# GD32E53x register map
File version: 1.0
CPU: CM33 r0p4, little endian, MPU, FPU, 4 interrupt priority bits
Registers are 32-bit, read-write, reset 0x0 unless marked. A register's access mark holds for its fields unless they carry their own. Offsets are from the block's base; [hi:lo] are bit positions; {n}, {i} and the like mark numbered series; 'fields as' and 'values as' point back to an identical list.

## RTC — Real time clock
Base 0x40002800
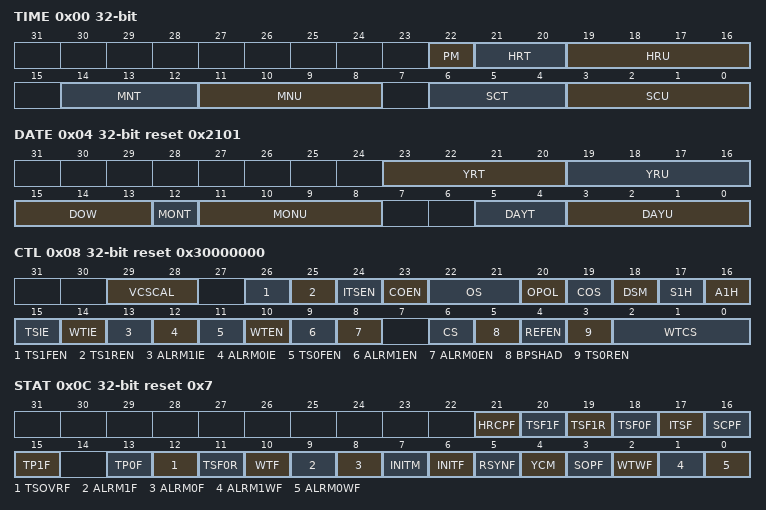
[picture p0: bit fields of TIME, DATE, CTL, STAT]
0x00 TIME
  [22] PM — AM/PM mark
  [21:20] HRT — Hour tens in BCD code
  [19:16] HRU — Hour units in BCD code
  [14:12] MNT — Minute tens in BCD code
  [11:8] MNU — Minute units in BCD code
  [6:4] SCT — Second tens in BCD code
  [3:0] SCU — Second units in BCD code
0x04 DATE reset 0x2101
  [23:20] YRT — Year tens in BCD code
  [19:16] YRU — Year units in BCD code
  [15:13] DOW — Days of the week
  [12] MONT — Month tens in BCD code
  [11:8] MONU — Month units in BCD code
  [5:4] DAYT — Day tens in BCD code
  [3:0] DAYU — Day units in BCD code
0x08 CTL access per field reset 0x30000000 — Control register
  [29:28] VCSCAL rw — BLDO voltage level selection
  [26] TS1FEN rw — RTC_TS1 time-stamp event falling edge enable
  [25] TS1REN rw — RTC_TS1 time-stamp event rising edge enable
  [24] ITSEN rw — Internal time-stamp event enable
  [23] COEN rw — Calibration output enable
  [22:21] OS rw — Output selection
  [20] OPOL rw — Output polarity
  [19] COS rw — Calibration output selection
  [18] DSM rw — Daylight saving mark
  [17] S1H wo — Subtract 1 hour(winter time change)
  [16] A1H wo — Add 1 hour(summer time change)
  [15] TSIE rw — Time-stamp interrupt enable
  [14] WTIE rw — Auto-wakeup timer interrupt enable
  [13] ALRM1IE rw — RTC alarm 1 interrupt enable
  [12] ALRM0IE rw — RTC alarm 0 interrupt enable
  [11] TS0FEN rw — RTC_TS0 time-stamp event falling edge enable
  [10] WTEN rw — Auto-wakeup timer function enable
  [9] ALRM1EN rw — Alarm 1 function enable
  [8] ALRM0EN rw — Alarm 0 function enable
  [6] CS rw — Clock System
  [5] BPSHAD rw — Shadow registers bypass control
  [4] REFEN rw — Reference clock detection function enable
  [3] TS0REN rw — RTC_TS0 time-stamp event rising edge enable
  [2:0] WTCS rw — Auto-wakeup timer clock selection
0x0C STAT access per field reset 0x7 — Status register
  [21] HRCPF ro — High-resolution calibration pending flag
  [20] TSF1F rw — Time-stamp1 falling edge event flag
  [19] TSF1R rw — Time-stamp1 rising edge event flag
  [18] TSF0F rw — Time-stamp 0 falling edge event flag
  [17] ITSF rw — Internal timestamp flag
  [16] SCPF ro — Smooth calibration pending flag
  [15] TP1F rw — RTC_TAMP1 detected flag
  [13] TP0F rw — RTC_TAMP0 detected flag
  [12] TSOVRF rw — Time-stamp overflow flag
  [11] TSF0R rw — Time-stamp 0 event rising edge flag
  [10] WTF rw — Wakeup timer flag
  [9] ALRM1F rw — Alarm 1 occurs flag
  [8] ALRM0F rw — Alarm 0 occurs flag
  [7] INITM rw — Enter initialization mode
  [6] INITF ro — Initialization state flag
  [5] RSYNF rw — Register synchronization flag
  [4] YCM ro — Year configuration mark
  [3] SOPF ro — Shift function operation pending flag
  [2] WTWF ro — Wakeup timer write enable flag
  [1] ALRM1WF ro — Alarm 1 configuration can be write flag
  [0] ALRM0WF ro — Alarm 0 configuration can be write flag
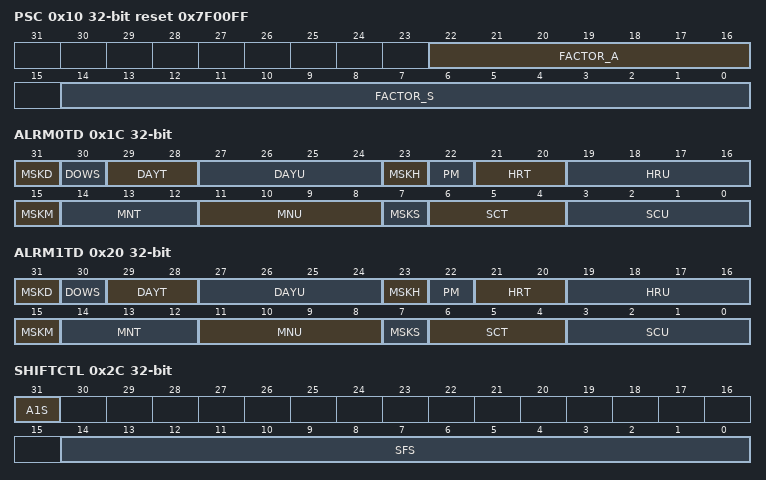
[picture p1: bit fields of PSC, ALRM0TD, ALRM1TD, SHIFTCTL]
0x10 PSC reset 0x7F00FF — Prescaler register
  [22:16] FACTOR_A — Asynchronous prescaler factor
  [14:0] FACTOR_S — Synchronous prescaler factor
0x14 WUT reset 0xFFFF — Wakeup timer register
  [15:0] WTRV — Auto-wakeup timer reloads value.
0x1C ALRM0TD — Alarm 0 time and date register
  [31] MSKD — Alarm date mask bit
  [30] DOWS — Day of the week selected
  [29:28] DAYT — Date tens in BCD code
  [27:24] DAYU — Date units or week day in BCD code
  [23] MSKH — Alarm hour mask bit
  [22] PM — AM/PM flag
  [21:20] HRT — Hour tens in BCD code
  [19:16] HRU — Hour units in BCD code
  [15] MSKM — Alarm minutes mask bit
  [14:12] MNT — Minutes tens in BCD code
  [11:8] MNU — Minutes units in BCD code
  [7] MSKS — Alarm second mask bit
  [6:4] SCT — Second tens in BCD code
  [3:0] SCU — Second units in BCD code
0x20 ALRM1TD — Alarm 1 time and date register
  [31] MSKD — Alarm date mask bit
  [30] DOWS — Day of the week selected
  [29:28] DAYT — Day tens in BCD code
  [27:24] DAYU — Day units or week day in BCD code
  [23] MSKH — Alarm hour mask bit
  [22] PM — AM/PM flag
  [21:20] HRT — Hour tens in BCD code
  [19:16] HRU — Hour units in BCD code
  [15] MSKM — Alarm minutes mask bit
  [14:12] MNT — Minutes tens in BCD code
  [11:8] MNU — Minutes units in BCD code
  [7] MSKS — Alarm second mask bit
  [6:4] SCT — Second tens in BCD code
  [3:0] SCU — Second units in BCD code
0x24 WPK wo — Write protection key register
  [7:0] WPK — Key for write protection
0x28 SS ro — Sub second register
  [15:0] SSC — Sub second value
0x2C SHIFTCTL wo — Shift function control register
  [31] A1S — One second add
  [14:0] SFS — Subtract a fraction of a second
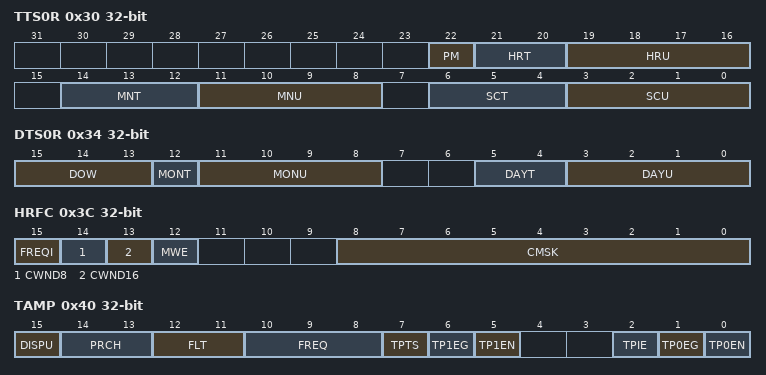
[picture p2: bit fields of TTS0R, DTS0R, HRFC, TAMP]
0x30 TTS0R ro — Time of time-stamp 0 rising register
  fields as TIME
0x34 DTS0R ro — Date of time-stamp 0 rising register
  [15:13] DOW — Days of the week
  [12] MONT — Month tens in BCD code
  [11:8] MONU — Month units in BCD code
  [5:4] DAYT — Day tens in BCD code
  [3:0] DAYU — Day units in BCD code
0x38 SSTS0R ro — Sub second of time-stamp 0 rising register
  [15:0] SSC — Sub second value
0x3C HRFC — High resolution frequency compensation register
  [15] FREQI — Increase RTC frequency by 488.5PPM
  [14] CWND8 — Frequency compensation window 8 second selected
  [13] CWND16 — Frequency compensation window 16 second selected
  [12] MWE — Multiple windows calibration enable.
  [8:0] CMSK — Calibration mask number
0x40 TAMP — Tamper register
  [15] DISPU — RTC_TAMPx pull up disable bit
  [14:13] PRCH — Pre-charge duration time of RTC_TAMPx
  [12:11] FLT — RTC_TAMPx filter count setting
  [10:8] FREQ — Sampling frequency of tamper event detection
  [7] TPTS — Make tamper function used for time-stamp 0 rising function
  [6] TP1EG — Tamper 1 event trigger edge
  [5] TP1EN — Tamper 1 detection enable
  [2] TPIE — Tamper detection interrupt enable
  [1] TP0EG — Tamper 0 event trigger edge
  [0] TP0EN — Tamper 0 detection enable
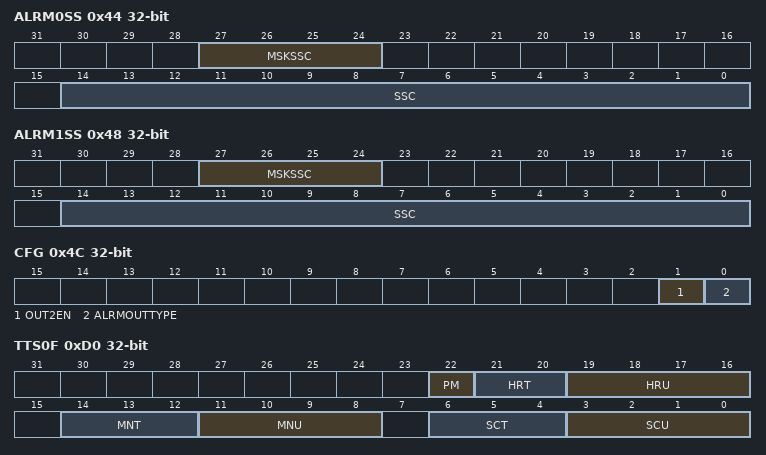
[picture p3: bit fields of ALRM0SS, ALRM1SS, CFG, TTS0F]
0x44 ALRM0SS — Alarm 0 sub second register
  [27:24] MSKSSC — Mask control bit of SSC
  [14:0] SSC — Alarm sub second value
0x48 ALRM1SS — Alarm 1 sub second register
  fields as ALRM0SS
0x4C CFG — Configuration register
  [1] OUT2EN — RTC_OUT pin select
  [0] ALRMOUTTYPE — RTC_ALARM Output Type
{0x50+4i} BKP{i} (i=0..3) — Backup registe {i}
  [31:0] DATA
0xD0 TTS0F ro — Time of time-stamp 0 falling register
  fields as TIME
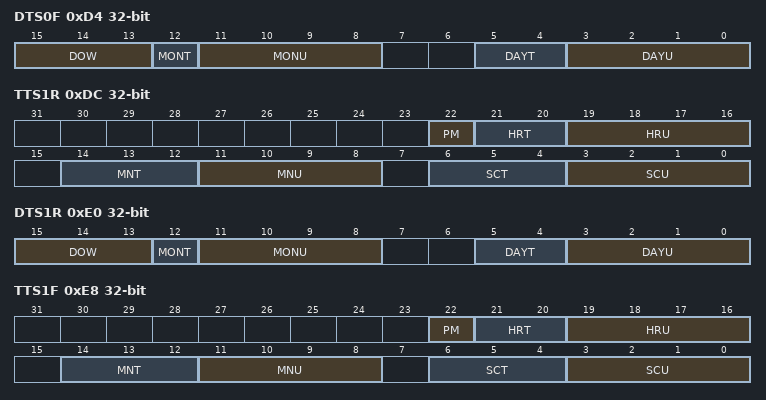
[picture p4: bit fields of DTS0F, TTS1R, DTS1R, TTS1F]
0xD4 DTS0F ro — Date of time-stamp 0 falling register
  fields as DTS0R
0xD8 SSTS0F ro — Sub second of time-stamp 0 falling register
  [15:0] SSC — Sub second value
0xDC TTS1R ro — Time of time-stamp 1 rising register
  fields as TIME
0xE0 DTS1R ro — Date of time-stamp 1 rising register
  fields as DTS0R
0xE4 SSTS1R ro — Sub second of time-stamp 1 rising register
  [15:0] SSC — Sub second value
0xE8 TTS1F ro — Time of time-stamp 1 falling register
  fields as TIME
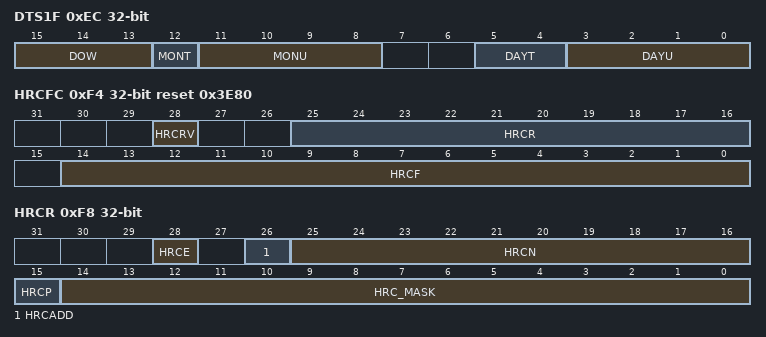
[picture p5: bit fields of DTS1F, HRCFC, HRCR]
0xEC DTS1F ro — Date of time-stamp 1 falling register
  fields as DTS0R
0xF0 SSTS1F ro — Sub second of time-stamp 1 falling register
  [15:0] SSC — Sub second value
0xF4 HRCFC reset 0x3E80 — High resolution clock frequence calibration registe
  [28] HRCRV — HRCR[9:0] valid
  [25:16] HRCR — The ratio of high-resolution calibration clock frequency to the RTC clock frequency. HRCR[9:0] is valid if HRCRV bit is set.
  [14:0] HRCF — High resolution calibration clock frequency The unit of frequency is KHz.
0xF8 HRCR — High-resolution calibration registe
  [28] HRCE — High-resolution calibration enable
  [26] HRCADD — The direction of adjusting HRCN[9:0] high-frequency clock cycles for RTC prescaler clock ck_spre.
  [25:16] HRCN — Number of high-frequency clock cycles for high-resolution calibration adjustment
  [15] HRCP — The prescaler clock ck_spre reduces one RTC clock cycle per sub-second.
  [14:0] HRC_MASK — Prescaler clock ck_spre increases HRC_MASK[14:0] RTC clock cycles.
